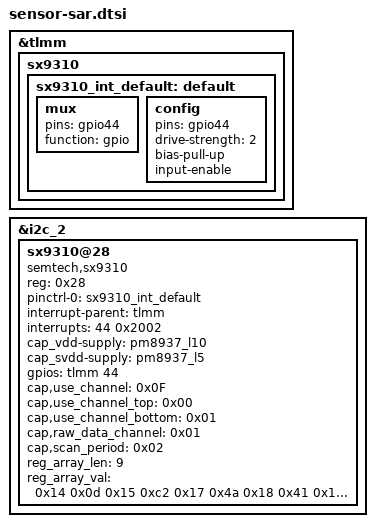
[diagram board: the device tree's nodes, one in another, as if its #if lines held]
#ifdef DEVICE_RHANNAH
&tlmm{
	/delete-node/ sx9310;
	sx9310:sx9310 {
		sx9310_int_default: default {
			mux {
				pins = "gpio44";
				function = "gpio";
			};

			config {
				pins = "gpio44";
				drive-strength = <2>;
				bias-pull-up;
				input-enable;
			};
		};
	};
};
#endif

&i2c_2 {
	sx9310@28 {
		compatible = "semtech,sx9310";
		reg = <0x28>;
		pinctrl-names = "default";
		pinctrl-0 = <&sx9310_int_default>;
		interrupt-parent = <&tlmm>;
		interrupts = <44 0x2002>;
		cap_vdd-supply = <&pm8937_l10>;
		cap_svdd-supply = <&pm8937_l5>;
		gpios = <&tlmm 44 0x2008>; /* IRQ */
		cap,use_channel = <0x0F>;
		cap,use_channel_top = <0x00>;
#ifdef DEVICE_HANNAH
		cap,use_channel_bottom = <0x01>;
#else
		cap,use_channel_bottom = <0x02>;
#endif
		cap,raw_data_channel = <0x01>;
		cap,scan_period = <0x02>;
#ifdef DEVICE_HANNAH
		reg_array_len = <9>;
		reg_array_val = <0x14 0x0d 0x15 0xc2 0x17 0x4a 0x18 0x41 0x19 0x31 0x1a 0x1f 0x21 0x1c 0x22 0x16 0x23 0x20>;
#else
		reg_array_len = <10>;
		reg_array_val = <0x12 0x03 0x13 0x0a 0x14 0x27 0x15 0xc3 0x17 0x4b 0x18 0x49 0x19 0x39 0x21 0x1a 0x22 0x05 0x23 0x20>;
#endif
	};
};
